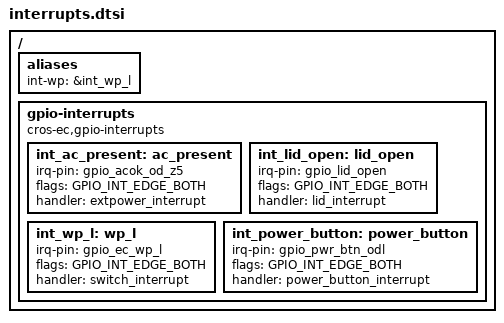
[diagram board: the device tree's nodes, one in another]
/* Copyright 2025 The ChromiumOS Authors
 * Use of this source code is governed by a BSD-style license that can be
 * found in the LICENSE file.
 */

/ {
	aliases {
		int-wp = &int_wp_l;
	};

	gpio-interrupts {
		compatible = "cros-ec,gpio-interrupts";

		int_ac_present: ac_present {
			irq-pin = <&gpio_acok_od_z5>;
			flags = <GPIO_INT_EDGE_BOTH>;
			handler = "extpower_interrupt";
		};
		int_lid_open: lid_open {
			irq-pin = <&gpio_lid_open>;
			flags = <GPIO_INT_EDGE_BOTH>;
			handler = "lid_interrupt";
		};
		int_wp_l: wp_l {
			irq-pin = <&gpio_ec_wp_l>;
			flags = <GPIO_INT_EDGE_BOTH>;
			handler = "switch_interrupt";
		};
		int_power_button: power_button {
			irq-pin = <&gpio_pwr_btn_odl>;
			flags = <GPIO_INT_EDGE_BOTH>;
			handler = "power_button_interrupt";
		};
	};
};
